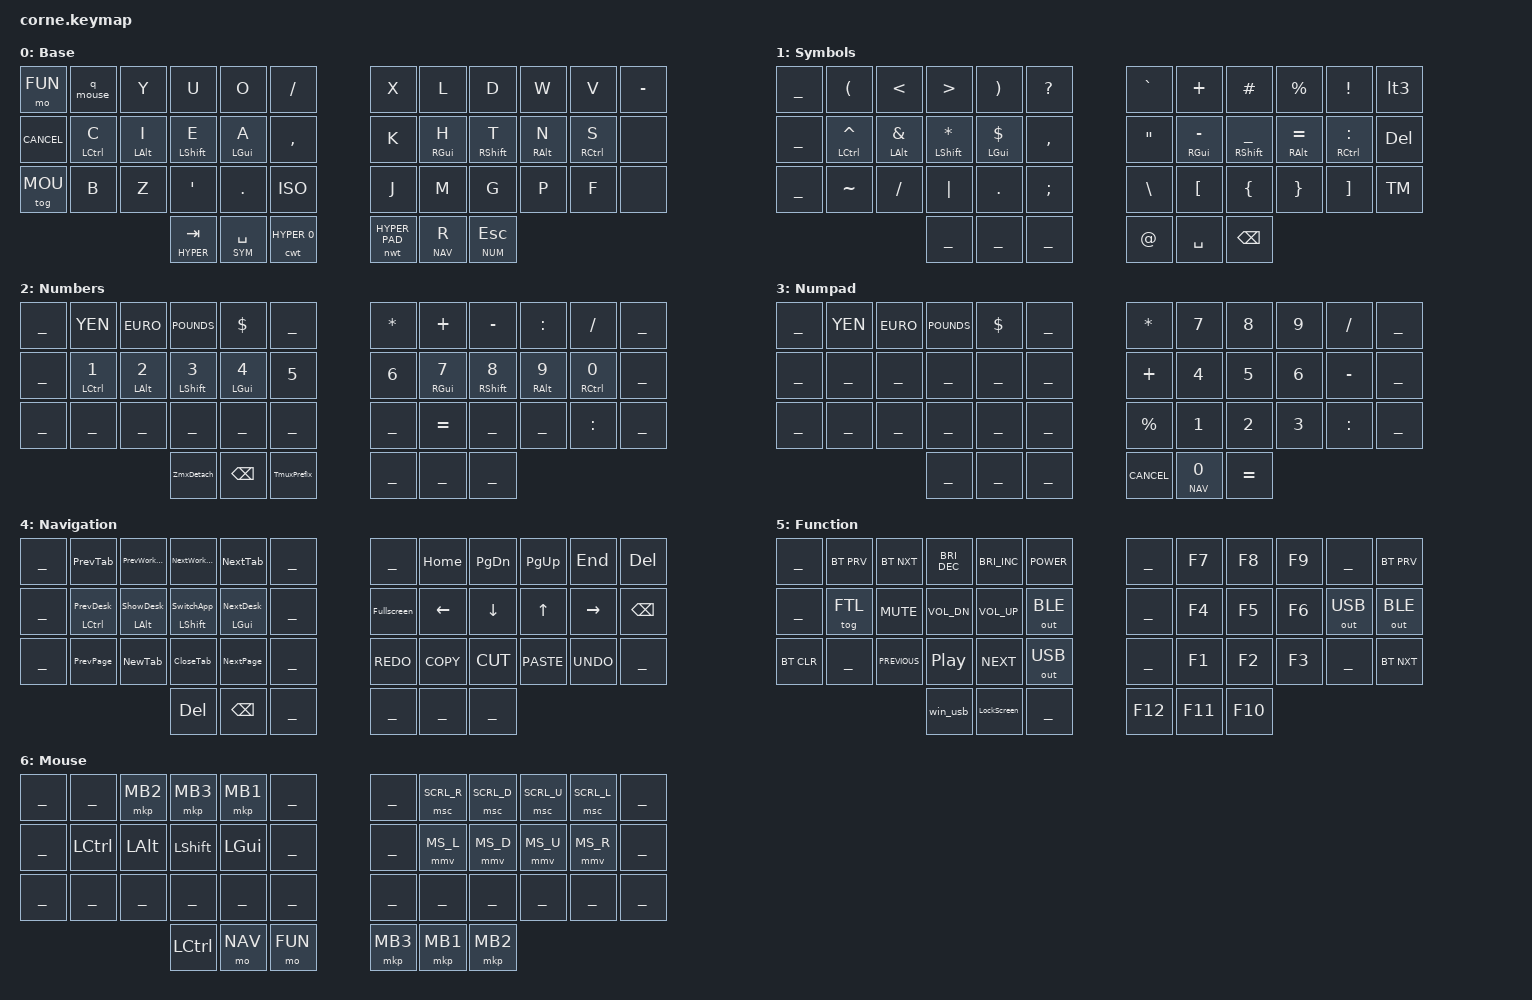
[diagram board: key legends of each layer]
#define CONFIG_WIRELESS
#include "zmk-helpers/key-labels/42.h"

#include <behaviors.dtsi>
#include <behaviors/num_word.dtsi>
#include <behaviors/unicode.dtsi> // Requires zmk-unicode module.
#include <zmk-helpers/helper.h> // Requires zmk-helpers module.
#include <dt-bindings/zmk/keys.h>
#ifdef CONFIG_WIRELESS
  #include <dt-bindings/zmk/bt.h>
  #include <dt-bindings/zmk/outputs.h>
#endif

#include "constants.dtsi"
#include "corne-mouse.dtsi"

#include "ftl.dtsi"

/* Keymap */

/ {
   keymap {
       compatible = "zmk,keymap";

       base_layer {
           display-name = "Base";
           bindings = <
//    ┌──────────┬────────────┬────────────┬──────────────┬────────────┬─────────────┐   ┌───────────────┬────────────┬─────────────┬────────────┬────────────┬───┐
//    │  mo FUN  │  &q_mouse  │     Y      │      U       │     O      │      /      │   │       X       │     L      │      D      │     W      │     V      │ - │
//    ├──────────┼────────────┼────────────┼──────────────┼────────────┼─────────────┤   ├───────────────┼────────────┼─────────────┼────────────┼────────────┼───┤
//    │ k_cancel │ hml lctl C │ hml lalt I │ hmls lsft E  │ hml lgui A │      ,      │   │       K       │ hmr rgui H │ hmrs rsft T │ hmr ralt N │ hmr rctl S │   │
//    ├──────────┼────────────┼────────────┼──────────────┼────────────┼─────────────┤   ├───────────────┼────────────┼─────────────┼────────────┼────────────┼───┤
//    │ tog MOU  │     B      │     Z      │      '       │     .      │      ä      │   │       J       │     M      │      G      │     P      │     F      │   │
//    └──────────┴────────────┴────────────┼──────────────┼────────────┼─────────────┤   ├───────────────┼────────────┼─────────────┼────────────┴────────────┴───┘
//                                         │ mt HYPER tab │ lt SYM spc │ cwt HYPER 0 │   │ nwt HYPER PAD │  lt NAV R  │ lt NUM esc  │
//                                         └──────────────┴────────────┴─────────────┘   └───────────────┴────────────┴─────────────┘
  &mo FUN        &q_mouse       &kp Y         &kp U           &kp O           &kp SLASH          &kp X            &kp L         &kp D           &kp W         &kp V          &kp MINUS
  &kp K_CANCEL   &hml LCTRL C   &hml LALT I   &hmls LSHFT E   &hml LGUI A     &kp COMMA          &kp K            &hmr RGUI H   &hmrs RSHFT T   &hmr RALT N   &hmr RCTRL S   &none
  &tog MOU       &kp B          &kp Z         &kp SQT         &kp DOT         &kp ISO            &kp J            &kp M         &kp G           &kp P         &kp F          &none
                                              &mt HYPER TAB   &lt SYM SPACE   &cwt HYPER 0       &nwt HYPER PAD   &lt NAV R     &lt NUM ESC
           >;
       };

       // Reserve WIN_MODE below the functional layers; windows.dtsi supplies bindings.
       win_mode_layer {};

       sym_layer {
           bindings = <
//    ┌────┬────────────┬────────────┬─────────────┬────────────┬────┐   ┌───┬────────────┬─────────────┬────────────┬────────────┬─────┐
//    │    │     (      │     <      │      >      │     )      │ ?  │   │ ` │     +      │      #      │     %      │     !      │ <3  │
//    ├────┼────────────┼────────────┼─────────────┼────────────┼────┤   ├───┼────────────┼─────────────┼────────────┼────────────┼─────┤
//    │    │ hml lctl ^ │ hml lalt & │ hmls lsft * │ hml lgui $ │ ,  │   │ " │ hmr rgui - │ hmrs rsft _ │ hmr ralt = │ hmr rctl : │ del │
//    ├────┼────────────┼────────────┼─────────────┼────────────┼────┤   ├───┼────────────┼─────────────┼────────────┼────────────┼─────┤
//    │    │     ~      │     /      │      |      │     .      │ ;  │   │ \ │     [      │      {      │     }      │     ]      │  ™  │
//    └────┴────────────┴────────────┼─────────────┼────────────┼────┤   ├───┼────────────┼─────────────┼────────────┴────────────┴─────┘
//                                   │             │            │    │   │ @ │    spc     │    bspc     │
//                                   └─────────────┴────────────┴────┘   └───┴────────────┴─────────────┘
  ___   &kp LEFT_PARENTHESIS   &kp LESS_THAN         &kp GREATER_THAN       &kp RIGHT_PARENTHESIS   &kp QUESTION        &kp GRAVE           &kp PLUS           &kp HASH                 &kp PERCENT       &kp EXCLAMATION     &lt3
  ___   &hml LCTRL CARET       &hml LALT AMPERSAND   &hmls LSHFT ASTERISK   &hml LGUI DOLLAR        &kp COMMA           &kp DOUBLE_QUOTES   &hmr RGUI MINUS    &hmrs RSHFT UNDERSCORE   &hmr RALT EQUAL   &hmr RCTRL COLON    &kp DELETE
  ___   &kp TILDE              &kp SLASH             &kp PIPE               &kp DOT                 &kp SEMICOLON       &kp BACKSLASH       &kp LEFT_BRACKET   &kp LEFT_BRACE           &kp RIGHT_BRACE   &kp RIGHT_BRACKET   &kp TM
                                                     ___                    ___                     ___                 &kp AT_SIGN         &kp SPACE          &kp BACKSPACE
           >;

           label = "Symbols";
       };

       num_layer {
           bindings = <
//    ┌────┬────────────┬────────────┬─────────────┬────────────┬────────────┐   ┌────┬────────────┬─────────────┬────────────┬────────────┬────┐
//    │    │     ¥      │     €      │      £      │     $      │            │   │ *  │     +      │      -      │     :      │     /      │    │
//    ├────┼────────────┼────────────┼─────────────┼────────────┼────────────┤   ├────┼────────────┼─────────────┼────────────┼────────────┼────┤
//    │    │ hml lctl 1 │ hml lalt 2 │ hmls lsft 3 │ hml lgui 4 │     5      │   │ 6  │ hmr rgui 7 │ hmrs rsft 8 │ hml ralt 9 │ hml rctl 0 │    │
//    ├────┼────────────┼────────────┼─────────────┼────────────┼────────────┤   ├────┼────────────┼─────────────┼────────────┼────────────┼────┤
//    │    │            │            │             │            │            │   │    │     =      │             │            │     :      │    │
//    └────┴────────────┴────────────┼─────────────┼────────────┼────────────┤   ├────┼────────────┼─────────────┼────────────┴────────────┴────┘
//                                   │  ZmxDetach  │    bspc    │ TmuxPrefix │   │    │            │             │
//                                   └─────────────┴────────────┴────────────┘   └────┴────────────┴─────────────┘
  ___   &kp YEN         &kp EURO       &kp POUNDS       &kp DOLLAR      ___                  &kp STAR   &kp PLUS       &kp MINUS        &kp COLON      &kp SLASH       ___
  ___   &hml LCTRL N1   &hml LALT N2   &hmls LSHFT N3   &hml LGUI N4    &kp N5               &kp N6     &hmr RGUI N7   &hmrs RSHFT N8   &hml RALT N9   &hml RCTRL N0   ___
  ___   ___             ___            ___              ___             ___                  ___        &kp EQUAL      ___              ___            &kp COLON       ___
                                       &kp ZmxDetach    &kp BACKSPACE   &kp TmuxPrefix       ___        ___            ___
           >;


           label = "Numbers";
       };

       pad_layer {
           display-name = "Numpad";
           bindings = <
//    ┌────┬────┬────┬────┬────┬────┐   ┌──────────┬──────────┬───┬───┬───┬────┐
//    │    │ ¥  │ €  │ £  │ $  │    │   │    *     │    7     │ 8 │ 9 │ / │    │
//    ├────┼────┼────┼────┼────┼────┤   ├──────────┼──────────┼───┼───┼───┼────┤
//    │    │    │    │    │    │    │   │    +     │    4     │ 5 │ 6 │ - │    │
//    ├────┼────┼────┼────┼────┼────┤   ├──────────┼──────────┼───┼───┼───┼────┤
//    │    │    │    │    │    │    │   │    %     │    1     │ 2 │ 3 │ : │    │
//    └────┴────┴────┼────┼────┼────┤   ├──────────┼──────────┼───┼───┴───┴────┘
//                   │    │    │    │   │ k_cancel │ lt NAV 0 │ = │
//                   └────┴────┴────┘   └──────────┴──────────┴───┘
  ___   &kp YEN   &kp EURO   &kp POUNDS   &kp DOLLAR   ___       &kp STAR       &kp N7       &kp N8      &kp N9   &kp SLASH   ___
  ___   ___       ___        ___          ___          ___       &kp PLUS       &kp N4       &kp N5      &kp N6   &kp MINUS   ___
  ___   ___       ___        ___          ___          ___       &kp PERCENT    &kp N1       &kp N2      &kp N3   &kp COLON   ___
                             ___          ___          ___       &kp K_CANCEL   &lt NAV N0   &kp EQUAL
           >;

           label = "Numpad";
       };

       nav_layer {
           bindings = <
//    ┌────┬───────────────────┬────────────────────┬────────────────────┬───────────────────┬────┐   ┌────────────┬──────┬──────┬───────┬──────┬──────┐
//    │    │      PrevTab      │    PrevWorkspc     │    NextWorkspc     │      NextTab      │    │   │            │ home │ pgdn │ pgup  │ end  │ del  │
//    ├────┼───────────────────┼────────────────────┼────────────────────┼───────────────────┼────┤   ├────────────┼──────┼──────┼───────┼──────┼──────┤
//    │    │ hml lctl PrevDesk │ hmls lalt ShowDesk │ hml lsft SwitchApp │ hml lgui NextDesk │    │   │ Fullscreen │ left │ down │  up   │ rght │ bspc │
//    ├────┼───────────────────┼────────────────────┼────────────────────┼───────────────────┼────┤   ├────────────┼──────┼──────┼───────┼──────┼──────┤
//    │    │     PrevPage      │       NewTab       │      CloseTab      │     NextPage      │    │   │    redo    │ copy │ cut  │ paste │ undo │      │
//    └────┴───────────────────┴────────────────────┼────────────────────┼───────────────────┼────┤   ├────────────┼──────┼──────┼───────┴──────┴──────┘
//                                                  │        del         │       bspc        │    │   │            │      │      │
//                                                  └────────────────────┴───────────────────┴────┘   └────────────┴──────┴──────┘
  ___   &kp PrevTab           &kp PrevWorkspc       &kp NextWorkspc        &kp NextTab          ___       ___              &kp HOME   &kp PG_DN   &kp PG_UP   &kp END     &kp DEL
  ___   &hml LCTRL PrevDesk   &hmls LALT ShowDesk   &hml LSHFT SwitchApp   &hml LGUI NextDesk   ___       &kp Fullscreen   &kp LEFT   &kp DOWN    &kp UP      &kp RIGHT   &kp BSPC
  ___   &kp PrevPage          &kp NewTab            &kp CloseTab           &kp NextPage         ___       &kp REDO         &kp COPY   &kp CUT     &kp PASTE   &kp UNDO    ___
                                                    &kp DEL                &kp BSPC             ___       ___              ___        ___
           >;

           label = "Navigation";
       };

       fn_layer {
           bindings = <
//    ┌────────┬─────────┬────────┬─────────┬────────────┬──────────┐   ┌─────┬─────┬─────┬────┬──────────┬──────────┐
//    │        │ bt_prv  │ bt_nxt │  bri-   │    bri+    │   pwr    │   │     │ f7  │ f8  │ f9 │          │  bt_prv  │
//    ├────────┼─────────┼────────┼─────────┼────────────┼──────────┤   ├─────┼─────┼─────┼────┼──────────┼──────────┤
//    │        │ tog FTL │  mute  │  vold   │    volu    │ out_ ble │   │     │ f4  │ f5  │ f6 │ out_ usb │ out_ ble │
//    ├────────┼─────────┼────────┼─────────┼────────────┼──────────┤   ├─────┼─────┼─────┼────┼──────────┼──────────┤
//    │ bt_clr │         │  prev  │  play   │    next    │ out_ usb │   │     │ f1  │ f2  │ f3 │          │  bt_nxt  │
//    └────────┴─────────┴────────┼─────────┼────────────┼──────────┤   ├─────┼─────┼─────┼────┴──────────┴──────────┘
//                                │ Win+USB │ LockScreen │          │   │ f12 │ f11 │ f10 │
//                                └─────────┴────────────┴──────────┘   └─────┴─────┴─────┘
  ___          &bt BT_PRV   &bt BT_NXT       &kp C_BRIGHTNESS_DEC   &kp C_BRIGHTNESS_INC   &kp C_POWER        ___       &kp F7    &kp F8    &kp F9   ___            &bt BT_PRV
  ___          &tog FTL     &kp C_MUTE       &kp C_VOL_DN           &kp C_VOLUME_UP        &out OUT_BLE       ___       &kp F4    &kp F5    &kp F6   &out OUT_USB   &out OUT_BLE
  &bt BT_CLR   ___          &kp C_PREVIOUS   &kp C_PLAY_PAUSE       &kp C_NEXT             &out OUT_USB       ___       &kp F1    &kp F2    &kp F3   ___            &bt BT_NXT
                                             &win_usb               &kp LockScreen         ___                &kp F12   &kp F11   &kp F10
           >;

           label = "Function";
       };

       mouse_layer {
           bindings = <
//    ┌────┬──────┬──────┬──────┬────────┬────────┐   ┌──────┬────────┬────────┬────────┬────────┬────┐
//    │    │      │ rclk │ mclk │  lclk  │        │   │      │ SCRL_R │ SCRL_D │ SCRL_U │ SCRL_L │    │
//    ├────┼──────┼──────┼──────┼────────┼────────┤   ├──────┼────────┼────────┼────────┼────────┼────┤
//    │    │ lctl │ lalt │ lsft │  lgui  │        │   │      │  MS_L  │  MS_D  │  MS_U  │  MS_R  │    │
//    ├────┼──────┼──────┼──────┼────────┼────────┤   ├──────┼────────┼────────┼────────┼────────┼────┤
//    │    │      │      │      │        │        │   │      │        │        │        │        │    │
//    └────┴──────┴──────┼──────┼────────┼────────┤   ├──────┼────────┼────────┼────────┴────────┴────┘
//                       │ lctl │ mo NAV │ mo FUN │   │ mclk │  lclk  │  rclk  │
//                       └──────┴────────┴────────┘   └──────┴────────┴────────┘
  ___   ___         &mkp MB2   &mkp MB3    &mkp MB1   ___           ___        &msc SCRL_R   &msc SCRL_D   &msc SCRL_U   &msc SCRL_L   ___
  ___   &kp LCTRL   &kp LALT   &kp LSHFT   &kp LGUI   ___           ___        &mmv MS_L     &mmv MS_D     &mmv MS_U     &mmv MS_R     ___
  ___   ___         ___        ___         ___        ___           ___        ___           ___           ___           ___           ___
                               &kp LCTRL   &mo NAV    &mo FUN       &mkp MB3   &mkp MB1      &mkp MB2
           >;

           label = "Mouse";
       };


   };
};
#include "windows.dtsi"
#include "ftl-layers.dtsi"
/{ chosen { zmk,physical-layout = &foostan_corne_6col_layout; }; };

/*
qmk:json:start
{
  "layout": [
    "x x x x x x _ x x x x x x",
    "x x x x x x _ x x x x x x",
    "x x x x x x _ x x x x x x",
    "_ _ _ x x x _ x x x _ _ _"
  ],
  "comment_preview": {
    "position": "top",
    "keymap_overrides": {
      "___": "  ",
      "&cwt": "cwt",
      "&hml": "hml",
      "&hmr": "hmr",
      "&hmls": "hmls",
      "&hmrs": "hmrs",
      "&nwt": "nwt",
      "&mmv ": "",
      "&msc ": "",
      "&num_word PAD": "numw",
      "&num_word": "numw",
      "&lt3": "<3",
      "&win_usb": "Win+USB",
      "ISO": "ä",
      "EURO": "€",
      "POUNDS": "£",
      "YEN": "¥",
      "TM": "™",
      "REDO": "redo",
      "CUT": "cut",
      "COPY": "copy",
      "PASTE": "paste",
      "UNDO": "undo",
      "&tog FTL": "tog FTL",
      "&none": " "
    }
  },
  "variant": "zmk"
}
qmk:json:end
*/
